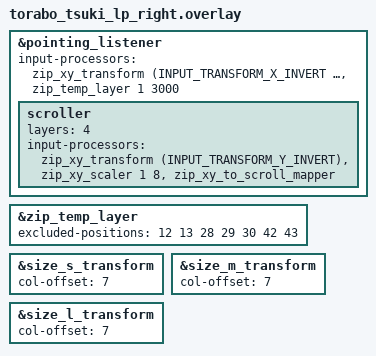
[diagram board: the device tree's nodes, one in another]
#define TORABO_TSUKI_LP_RIGHT 1

#include "torabo_tsuki_lp.dtsi"
#include <input/processors.dtsi>
#include <dt-bindings/zmk/input_transform.h>

&pointing_listener {
    input-processors = <&zip_xy_transform (INPUT_TRANSFORM_X_INVERT | INPUT_TRANSFORM_Y_INVERT) &zip_temp_layer 1 3000>;
    scroller {
        layers = <4>;
        input-processors = <&zip_xy_transform (INPUT_TRANSFORM_Y_INVERT) &zip_xy_scaler 1 8 &zip_xy_to_scroll_mapper>;
    };
};

&zip_temp_layer {
    excluded-positions = <12 13 28 29 30 42 43>;
};

&size_s_transform {
    col-offset = <7>;
};

&size_m_transform {
    col-offset = <7>;
};

&size_l_transform {
    col-offset = <7>;
};
